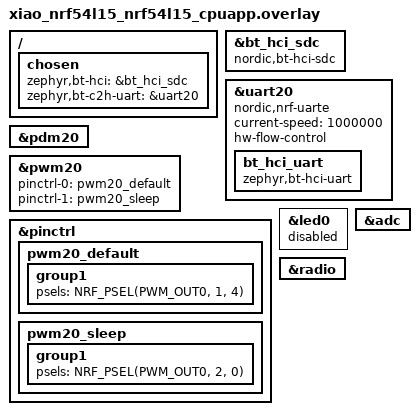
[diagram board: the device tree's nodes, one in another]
// To get started, press Ctrl+Space to bring up the completion menu and view the available nodes.

// You can also use the buttons in the sidebar to perform actions on nodes.
// Actions currently available include:

// * Enabling / disabling the node
// * Adding the bus to a bus
// * Removing the node
// * Connecting ADC channels

// For more help, browse the DeviceTree documentation at https://docs.zephyrproject.org/latest/guides/dts/index.html
// You can also visit the nRF DeviceTree extension documentation at https://docs.nordicsemi.com/bundle/nrf-connect-vscode/page/guides/ncs_configure_app.html#devicetree-support-in-the-extension
/ {
   chosen {
        zephyr,bt-hci = &bt_hci_sdc;
        zephyr,bt-c2h-uart = &uart20;
   };
};


&bt_hci_sdc {
    compatible = "nordic,bt-hci-sdc";
    status = "okay";
};

&uart20 {
	compatible = "nordic,nrf-uarte";
	current-speed = <1000000>;
	status = "okay";
	hw-flow-control;
};



&uart20 {
   status = "okay";
   bt_hci_uart: bt_hci_uart {
      compatible = "zephyr,bt-hci-uart";
      status = "okay";
   };
};
&pdm20 {
   status = "okay";
};

&pwm20 {
   status = "okay";
   pinctrl-0 = <&pwm20_default>;
   pinctrl-1 = <&pwm20_sleep>;
   pinctrl-names = "default", "sleep";
};

&pinctrl {
   pwm20_default: pwm20_default {
      group1 {
         psels = <NRF_PSEL(PWM_OUT0, 1, 4)>;
      };
   };

   pwm20_sleep: pwm20_sleep {
      group1 {
         psels = <NRF_PSEL(PWM_OUT0, 2, 0)>;
      };
   };
};

&led0 {
   status = "disabled";
};

&adc {
   status = "okay";
};

&radio {
   status = "okay";
};
